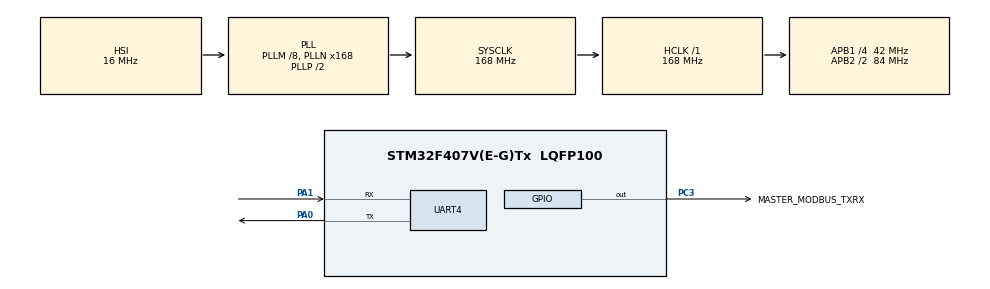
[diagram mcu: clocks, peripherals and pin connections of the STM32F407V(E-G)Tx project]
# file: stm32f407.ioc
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Dma.Request0=UART4_RX
Dma.Request1=UART4_TX
Dma.UART4_RX.0.Direction=DMA_PERIPH_TO_MEMORY
Dma.UART4_RX.0.FIFOMode=DMA_FIFOMODE_DISABLE
Dma.UART4_RX.0.Instance=DMA1_Stream2
Dma.UART4_RX.0.MemDataAlignment=DMA_MDATAALIGN_BYTE
Dma.UART4_RX.0.MemInc=DMA_MINC_ENABLE
Dma.UART4_RX.0.Mode=DMA_NORMAL
Dma.UART4_RX.0.PeriphDataAlignment=DMA_PDATAALIGN_BYTE
Dma.UART4_RX.0.PeriphInc=DMA_PINC_DISABLE
Dma.UART4_RX.0.Priority=DMA_PRIORITY_LOW
Dma.UART4_TX.1.Direction=DMA_MEMORY_TO_PERIPH
Dma.UART4_TX.1.FIFOMode=DMA_FIFOMODE_DISABLE
Dma.UART4_TX.1.Instance=DMA1_Stream4
Dma.UART4_TX.1.MemDataAlignment=DMA_MDATAALIGN_BYTE
Dma.UART4_TX.1.MemInc=DMA_MINC_ENABLE
Dma.UART4_TX.1.Mode=DMA_NORMAL
Dma.UART4_TX.1.PeriphDataAlignment=DMA_PDATAALIGN_BYTE
Dma.UART4_TX.1.PeriphInc=DMA_PINC_DISABLE
Dma.UART4_TX.1.Priority=DMA_PRIORITY_LOW
Mcu.Family=STM32F4
Mcu.Name=STM32F407V(E-G)Tx
Mcu.Package=LQFP100
NVIC.DMA1_Stream2_IRQn=true\:0\:0\:false\:false\:true\:false\:true\:true
NVIC.DMA1_Stream4_IRQn=true\:0\:0\:false\:false\:true\:false\:true\:true
NVIC.PriorityGroup=NVIC_PRIORITYGROUP_4
NVIC.TIM6_DAC_IRQn=true\:0\:0\:false\:false\:true\:true\:true\:true
NVIC.UART4_IRQn=true\:0\:0\:false\:false\:true\:true\:true\:true
PA0-WKUP.Mode=Asynchronous
PA0-WKUP.Signal=UART4_TX
PA1.Mode=Asynchronous
PA1.Signal=UART4_RX
PA13.Mode=Serial_Wire
PA13.Signal=SYS_JTMS-SWDIO
PA14.Mode=Serial_Wire
PA14.Signal=SYS_JTCK-SWCLK
PC3.GPIO_Label=MASTER_MODBUS_TXRX
PC3.GPIO_PuPd=GPIO_PULLUP
PC3.PinState=GPIO_PIN_SET
PC3.Signal=GPIO_Output
PH0-OSC_IN.Mode=HSE-External-Oscillator
PH0-OSC_IN.Signal=RCC_OSC_IN
PH1-OSC_OUT.Mode=HSE-External-Oscillator
PH1-OSC_OUT.Signal=RCC_OSC_OUT
ProjectManager.HeapSize=0x400
ProjectManager.StackSize=0x800
ProjectManager.TargetToolchain=MDK-ARM V5.32
RCC.48MHZClocksFreq_Value=84000000
RCC.AHBFreq_Value=168000000
RCC.APB1CLKDivider=RCC_HCLK_DIV4
RCC.APB1Freq_Value=42000000
RCC.APB1TimFreq_Value=84000000
RCC.APB2CLKDivider=RCC_HCLK_DIV2
RCC.APB2Freq_Value=84000000
RCC.APB2TimFreq_Value=168000000
RCC.CortexFreq_Value=168000000
RCC.HCLKFreq_Value=168000000
RCC.HSE_VALUE=8000000
RCC.HSI_VALUE=16000000
RCC.LSE_VALUE=32768
RCC.PLLM=8
RCC.PLLN=168
RCC.SYSCLKFreq_VALUE=168000000
RCC.SYSCLKSource=RCC_SYSCLKSOURCE_PLLCLK
RCC.VCOOutputFreq_Value=336000000
TIM6.AutoReloadPreload=TIM_AUTORELOAD_PRELOAD_ENABLE
TIM6.Period=1000
TIM6.Prescaler=42-1
UART4.VirtualMode=Asynchronous
VP_TIM6_VS_ClockSourceINT.Mode=Enable_Timer
board=custom

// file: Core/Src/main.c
/* USER CODE BEGIN Header */
/**
  ******************************************************************************
  * @file           : main.c
  * @brief          : Main program body
  ******************************************************************************
  * @attention
  *
  * Copyright (c) 2022 STMicroelectronics.
  * All rights reserved.
  *
  * This software is licensed under terms that can be found in the LICENSE file
  * in the root directory of this software component.
  * If no LICENSE file comes with this software, it is provided AS-IS.
  *
  ******************************************************************************
  */
/* USER CODE END Header */
#include "main.h"
#include "dma.h"
#include "tim.h"
#include "usart.h"
#include "gpio.h"

/* USER CODE BEGIN Includes */
#include "ModbusMaster.h"

/* USER CODE END Includes */

void SystemClock_Config(void);

/* USER CODE BEGIN 0 */
uint8_t flag1 = 0;
/* USER CODE END 0 */

int main(void)
{

  /* MCU Configuration--------------------------------------------------------*/

  /* Reset of all peripherals, Initializes the Flash interface and the Systick. */
  HAL_Init();

  /* Configure the system clock */
  SystemClock_Config();

  /* Initialize all configured peripherals */
  MX_GPIO_Init();
  MX_DMA_Init();
  MX_TIM6_Init();
  MX_UART4_Init();
  /* USER CODE BEGIN 2 */

	HAL_TIM_Base_Start_IT(&htim6);//以中断方式启动定时器
	ModbusMasterDealType.InitCall(&ModbusMasterDealType);//Modbus主机初始化

  /* USER CODE END 2 */

  /* Infinite loop */
  /* USER CODE BEGIN WHILE */

	ModbusMasterDealType.SendWriteAllCall(&ModbusMasterDealType,TestRegister1,1);

	uint8_t flag = 0;

  while (1)
  {
	 if((ModbusMasterDealType.TimeType.PublicClock_ms % 300) == 0){
		 if(flag == 0){
			flag = 1;
			ModbusMasterDealType.SendReadAllCall(&ModbusMasterDealType,TestRegister1,2);
		 }

	 }else{
		flag = 0;
	 }
	 if((ModbusMasterDealType.TimeType.PublicClock_ms % 1000) == 0){
		 if(flag1 == 0){
			flag1 = 1;
			ModbusMasterDealType.SendWriteAllCall(&ModbusMasterDealType,TestRegister2,1);
		 }

	 }else{
		//flag1 = 0;
	 }

    /* USER CODE END WHILE */

    /* USER CODE BEGIN 3 */
	  ModbusMasterDealType.ReceiveTaskDealCall(&ModbusMasterDealType);
	  ModbusMasterDealType.SendTaskDealCall(&ModbusMasterDealType);
  }
  /* USER CODE END 3 */
}

void SystemClock_Config(void)
{
  RCC_OscInitTypeDef RCC_OscInitStruct = {0};
  RCC_ClkInitTypeDef RCC_ClkInitStruct = {0};

  /** Configure the main internal regulator output voltage
  */
  __HAL_RCC_PWR_CLK_ENABLE();
  __HAL_PWR_VOLTAGESCALING_CONFIG(PWR_REGULATOR_VOLTAGE_SCALE1);

  /** Initializes the RCC Oscillators according to the specified parameters
  * in the RCC_OscInitTypeDef structure.
  */
  RCC_OscInitStruct.OscillatorType = RCC_OSCILLATORTYPE_HSI;
  RCC_OscInitStruct.HSIState = RCC_HSI_ON;
  RCC_OscInitStruct.HSICalibrationValue = RCC_HSICALIBRATION_DEFAULT;
  RCC_OscInitStruct.PLL.PLLState = RCC_PLL_ON;
  RCC_OscInitStruct.PLL.PLLSource = RCC_PLLSOURCE_HSI;
  RCC_OscInitStruct.PLL.PLLM = 8;
  RCC_OscInitStruct.PLL.PLLN = 168;
  RCC_OscInitStruct.PLL.PLLP = RCC_PLLP_DIV2;
  RCC_OscInitStruct.PLL.PLLQ = 4;
  if (HAL_RCC_OscConfig(&RCC_OscInitStruct) != HAL_OK)
  {
    Error_Handler();
  }

  /** Initializes the CPU, AHB and APB buses clocks
  */
  RCC_ClkInitStruct.ClockType = RCC_CLOCKTYPE_HCLK|RCC_CLOCKTYPE_SYSCLK
                              |RCC_CLOCKTYPE_PCLK1|RCC_CLOCKTYPE_PCLK2;
  RCC_ClkInitStruct.SYSCLKSource = RCC_SYSCLKSOURCE_PLLCLK;
  RCC_ClkInitStruct.AHBCLKDivider = RCC_SYSCLK_DIV1;
  RCC_ClkInitStruct.APB1CLKDivider = RCC_HCLK_DIV4;
  RCC_ClkInitStruct.APB2CLKDivider = RCC_HCLK_DIV2;

  if (HAL_RCC_ClockConfig(&RCC_ClkInitStruct, FLASH_LATENCY_5) != HAL_OK)
  {
    Error_Handler();
  }
}

void Error_Handler(void)
{
  __disable_irq();
  while (1)
  {
  }
}
